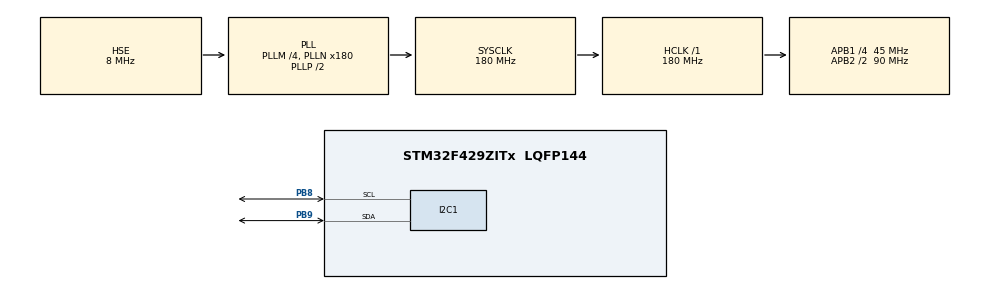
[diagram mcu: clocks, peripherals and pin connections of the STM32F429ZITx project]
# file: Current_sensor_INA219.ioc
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Mcu.Family=STM32F4
RCC.PLLSourceVirtual=RCC_PLLSOURCE_HSE
RCC.CortexFreq_Value=180000000
RCC.SYSCLKSourceVirtual=RCC_SYSCLKSOURCE_PLLCLK
RCC.APB1CLKDivider=RCC_HCLK_DIV4
RCC.SYSCLKSource=RCC_SYSCLKSOURCE_PLLCLK
ProjectManager.StackSize=0x800
PA13.Signal=SYS_JTMS-SWDIO
ProjectManager.TargetToolchain=STM32CubeIDE
PH0/OSC_IN.Mode=HSE-External-Oscillator
RCC.HCLKFreq_Value=180000000
PB9.Mode=I2C
RCC.APB2TimFreq_Value=180000000
PH1/OSC_OUT.Signal=RCC_OSC_OUT
RCC.USBFreq_Value=48000000
RCC.LSE_VALUE=32768
RCC.AHBFreq_Value=180000000
RCC.HSE_VALUE=8000000
board=NUCLEO-F429ZI
RCC.VCOOutputFreq_Value=360000000
RCC.PLLMUL=RCC_PLL_MUL9
PH0/OSC_IN.Signal=RCC_OSC_IN
RCC.APB2Freq_Value=90000000
RCC.PRESCALERUSB=RCC_USBCLKSOURCE_PLL_DIV1_5
PA14.Mode=Serial_Wire
PA13.Mode=Serial_Wire
PH1/OSC_OUT.Mode=HSE-External-Oscillator
Mcu.Name=STM32F429ZITx
RCC.48MHZClocksFreq_Value=120000000
RCC.SYSCLKFreq_VALUE=180000000
PB9.Signal=I2C1_SDA
Mcu.Package=LQFP144
PA14.Signal=SYS_JTCK-SWCLK
ProjectManager.HeapSize=0x400
RCC.HSI_VALUE=16000000
RCC.PLLQ=3
NVIC.PriorityGroup=NVIC_PRIORITYGROUP_4
RCC.APB2CLKDivider=RCC_HCLK_DIV2
RCC.PLLM=4
PB8.Mode=I2C
RCC.PLLN=180
RCC.APB1TimFreq_Value=90000000
PB8.Signal=I2C1_SCL
RCC.APB1Freq_Value=45000000

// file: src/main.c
/* USER CODE BEGIN Header */
/**
  ******************************************************************************
  * @file           : main.c
  * @brief          : Main program body
  ******************************************************************************
  * @attention
  *
  * <h2><center>&copy; Copyright (c) 2022 STMicroelectronics.
  * All rights reserved.</center></h2>
  *
  * This software component is licensed by ST under BSD 3-Clause license,
  * the "License"; You may not use this file except in compliance with the
  * License. You may obtain a copy of the License at:
  *                        opensource.org/licenses/BSD-3-Clause
  *
  ******************************************************************************
  */
/* USER CODE END Header */
#include "main.h"

/* USER CODE BEGIN Includes */
#include <math.h>
// Current constants
#define	c1      0.086103
#define	c2      15.056

//Power  constants
#define	p1     1.6283
#define	p2     32.4321

// Voltage constants
#define value  -19
#define v1   2.8672*exp(value)
#define v2   12

/* USER CODE END Includes */

I2C_HandleTypeDef hi2c1;

/* USER CODE BEGIN PV */
extern int adrs_219;

/* USER CODE END PV */

void SystemClock_Config(void);
static void MX_GPIO_Init(void);
static void MX_I2C1_Init(void);

// Parameters to monitor
uint32_t Current;
uint32_t Power;
uint32_t Voltage;

uint32_t Current1;
uint32_t Power1;
uint32_t Voltage1;

//uint32_t Syst_clk;

uint32_t ina_curr =0;
uint32_t ina_vol =0;
uint32_t ina_pwr =0;

uint32_t ina_curr1 =0;
uint32_t ina_vol1 =0;
uint32_t ina_pwr1 =0;

/* USER CODE END 0 */

int main(void)
{

  /* MCU Configuration--------------------------------------------------------*/

  /* Reset of all peripherals, Initializes the Flash interface and the Systick. */
  HAL_Init();

  /* Configure the system clock */
  SystemClock_Config();

  /* Initialize all configured peripherals */
  MX_GPIO_Init();
  MX_I2C1_Init();
  /* USER CODE BEGIN 2 */
	    adrs_219 = 0x40;
	    setCalibration_32V_2A();

  /* USER CODE END 1 */

  /* USER CODE BEGIN SysInit */

  /* USER CODE END SysInit */

  /* Initialize all configured peripherals */

  /* USER CODE BEGIN 2 */

  /* USER CODE END 2 */

  /* Infinite loop */
  while (1)
  {

    /* USER CODE BEGIN 3 */

	  adrs_219 = 0x40;
      ina_curr = getCurrent_mA();
      Current = c1*ina_curr - c2; // Current consumption in mA
      ina_pwr = getPower_mW();
      Power = p1*ina_pwr - p2; // Power consumption in mA
      ina_vol = getBusVoltage_V();
      Voltage = v1*ina_vol - v2; // Voltage in Volts
      HAL_Delay(10);
      Syst_clk =HAL_RCC_GetSysClockFreq();

  }
  /* USER CODE END 3 */
}

void SystemClock_Config(void)
{
  RCC_OscInitTypeDef RCC_OscInitStruct = {0};
  RCC_ClkInitTypeDef RCC_ClkInitStruct = {0};

  /** Configure the main internal regulator output voltage
  */
  __HAL_RCC_PWR_CLK_ENABLE();
  __HAL_PWR_VOLTAGESCALING_CONFIG(PWR_REGULATOR_VOLTAGE_SCALE1);
  /** Initializes the RCC Oscillators according to the specified parameters
  * in the RCC_OscInitTypeDef structure.
  */
  RCC_OscInitStruct.OscillatorType = RCC_OSCILLATORTYPE_HSE;
  RCC_OscInitStruct.HSEState = RCC_HSE_ON;
  RCC_OscInitStruct.PLL.PLLState = RCC_PLL_ON;
  RCC_OscInitStruct.PLL.PLLSource = RCC_PLLSOURCE_HSE;
  RCC_OscInitStruct.PLL.PLLM = 4;
  RCC_OscInitStruct.PLL.PLLN = 180;
  RCC_OscInitStruct.PLL.PLLP = RCC_PLLP_DIV2;
  RCC_OscInitStruct.PLL.PLLQ = 3;
  if (HAL_RCC_OscConfig(&RCC_OscInitStruct) != HAL_OK)
  {
    Error_Handler();
  }
  /** Activate the Over-Drive mode
  */
  if (HAL_PWREx_EnableOverDrive() != HAL_OK)
  {
    Error_Handler();
  }
  /** Initializes the CPU, AHB and APB buses clocks
  */
  RCC_ClkInitStruct.ClockType = RCC_CLOCKTYPE_HCLK|RCC_CLOCKTYPE_SYSCLK
                              |RCC_CLOCKTYPE_PCLK1|RCC_CLOCKTYPE_PCLK2;
  RCC_ClkInitStruct.SYSCLKSource = RCC_SYSCLKSOURCE_PLLCLK;
  RCC_ClkInitStruct.AHBCLKDivider = RCC_SYSCLK_DIV1;
  RCC_ClkInitStruct.APB1CLKDivider = RCC_HCLK_DIV4;
  RCC_ClkInitStruct.APB2CLKDivider = RCC_HCLK_DIV2;

  if (HAL_RCC_ClockConfig(&RCC_ClkInitStruct, FLASH_LATENCY_5) != HAL_OK)
  {
    Error_Handler();
  }
}

static void MX_I2C1_Init(void)
{

  hi2c1.Instance = I2C1;
  hi2c1.Init.ClockSpeed = 100000;
  hi2c1.Init.DutyCycle = I2C_DUTYCYCLE_2;
  hi2c1.Init.OwnAddress1 = 0;
  hi2c1.Init.AddressingMode = I2C_ADDRESSINGMODE_7BIT;
  hi2c1.Init.DualAddressMode = I2C_DUALADDRESS_DISABLE;
  hi2c1.Init.OwnAddress2 = 0;
  hi2c1.Init.GeneralCallMode = I2C_GENERALCALL_DISABLE;
  hi2c1.Init.NoStretchMode = I2C_NOSTRETCH_DISABLE;
  if (HAL_I2C_Init(&hi2c1) != HAL_OK)
  {
    Error_Handler();
  }
  /** Configure Analogue filter
  */
  if (HAL_I2CEx_ConfigAnalogFilter(&hi2c1, I2C_ANALOGFILTER_ENABLE) != HAL_OK)
  {
    Error_Handler();
  }
  /** Configure Digital filter
  */
  if (HAL_I2CEx_ConfigDigitalFilter(&hi2c1, 0) != HAL_OK)
  {
    Error_Handler();
  }

}

static void MX_GPIO_Init(void)
{

  /* GPIO Ports Clock Enable */
  __HAL_RCC_GPIOH_CLK_ENABLE();
  __HAL_RCC_GPIOA_CLK_ENABLE();
  __HAL_RCC_GPIOB_CLK_ENABLE();

}

void Error_Handler(void)
{
  __disable_irq();
  while (1)
  {
  }
}

/************************ (C) COPYRIGHT STMicroelectronics *****END OF FILE****/
